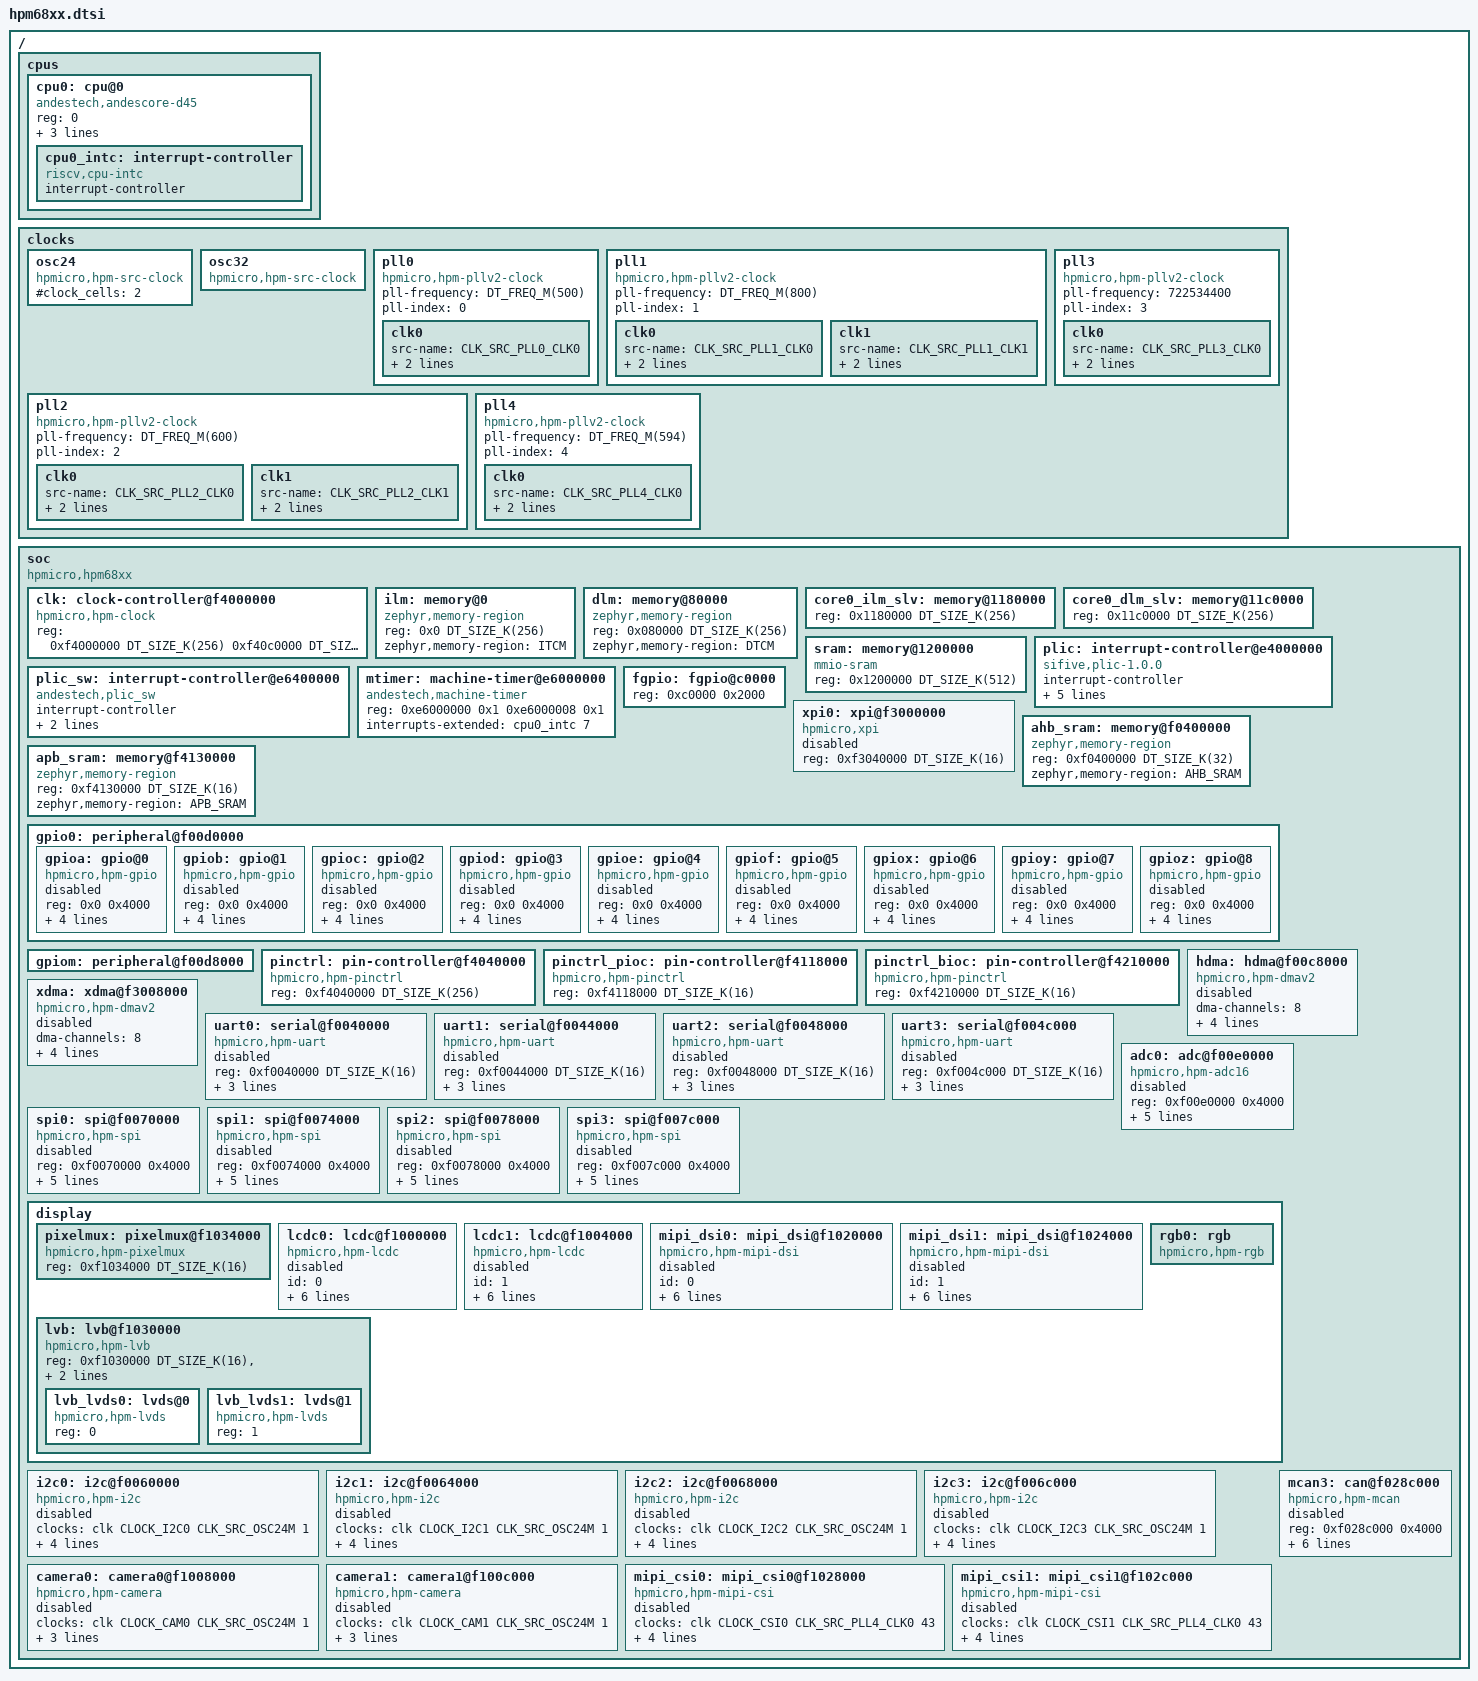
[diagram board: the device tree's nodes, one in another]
/*
 * Copyright 2024 HPMicro
 * SPDX-License-Identifier: Apache-2.0
 */

/dts-v1/;
#include <zephyr/dt-bindings/gpio/gpio.h>
#include <zephyr/dt-bindings/i2c/i2c.h>
#include <dt-bindings/clock/hpm6880-clocks.h>
#include <mem.h>
#include <freq.h>


/ {
    #address-cells = <1>;
    #size-cells = <1>;

    cpus {
        #address-cells = <1>;
        #size-cells = <0>;
        cpu0: cpu@0 {
            compatible = "andestech,andescore-d45", "riscv";
            reg = <0>;
            status = "okay";
            riscv,isa = "rv32gcp_xandes";       /* support SIMD DSP */
            i-cache-line-size = <64>;
            d-cache-line-size = <64>;

            cpu0_intc: interrupt-controller {
                compatible = "riscv,cpu-intc";
                #address-cells = <0>;
                #interrupt-cells = <1>;
                interrupt-controller;
            };
        };
    };

    clocks {
        osc24: osc24 {
            #clock_cells = <2>;
            compatible = "hpmicro,hpm-src-clock";
        };

		osc32: osc32 {
			#clock-cells = <2>;
			compatible = "hpmicro,hpm-src-clock";
		};

		pll0: pll0 {
			#clock-cells = <2>;
			compatible = "hpmicro,hpm-pllv2-clock";
			pll-frequency = <DT_FREQ_M(500)>;
			pll-index = <0>;

			clk0 {
				src-name = <CLK_SRC_PLL0_CLK0>;
				div-i = <0>;
				div-p = <0>;
			};
		};

		pll1: pll1 {
			#clock-cells = <2>;
			compatible = "hpmicro,hpm-pllv2-clock";
			pll-frequency = <DT_FREQ_M(800)>;
			pll-index = <1>;

			clk0 {
				src-name = <CLK_SRC_PLL1_CLK0>;
				div-i = <0>;
				div-p = <0>;
			};

			clk1 {
				src-name = <CLK_SRC_PLL1_CLK1>;
				div-i = <1>;
				div-p = <1>;
			};
		};

		pll2: pll2 {
			#clock-cells = <2>;
			compatible = "hpmicro,hpm-pllv2-clock";
			pll-frequency = <DT_FREQ_M(600)>;
			pll-index = <2>;

			clk0 {
				src-name = <CLK_SRC_PLL2_CLK0>;
				div-i = <0>;
				div-p = <0>;
			};

			clk1 {
				src-name = <CLK_SRC_PLL2_CLK1>;
				div-i = <1>;
				div-p = <1>;
			};
		};

		pll3: pll3 {
			#clock-cells = <2>;
			compatible = "hpmicro,hpm-pllv2-clock";
			pll-frequency = <722534400>;
			pll-index = <3>;

			clk0 {
				src-name = <CLK_SRC_PLL3_CLK0>;
				div-i = <0>;
				div-p = <2>;				
			};
		};

		pll4: pll4 {
			#clock-cells = <2>;
			compatible = "hpmicro,hpm-pllv2-clock";
			pll-frequency = <DT_FREQ_M(594)>;
			pll-index = <4>;

			clk0 {
				src-name = <CLK_SRC_PLL4_CLK0>;
				div-i = <0>;
				div-p = <0>;
			};
		};
    };

    soc {
        #address-cells = <1>;
        #size-cells = <1>;
        compatible = "hpmicro,hpm68xx";
        ranges;

        clk: clock-controller@f4000000 {
            compatible = "hpmicro,hpm-clock";
            reg = <0xf4000000 DT_SIZE_K(256)
                0xf40c0000 DT_SIZE_K(256)>;
            reg-names = "sysctl", "pll";
            #clock-cells = <3>;
            status = "okay";
        };

        ilm: memory@0 {
            compatible = "zephyr,memory-region";
            reg = <0x0 DT_SIZE_K(256)>;
            zephyr,memory-region = "ITCM";
        };

        dlm: memory@80000 {
            compatible = "zephyr,memory-region";
            reg = <0x080000 DT_SIZE_K(256)>;
            zephyr,memory-region = "DTCM";
        };

        core0_ilm_slv: memory@1180000 {
            reg = <0x1180000 DT_SIZE_K(256)>;
        };

        core0_dlm_slv: memory@11c0000 {
            reg = <0x11c0000 DT_SIZE_K(256)>;
        };

        sram: memory@1200000 {
            compatible = "mmio-sram";
            reg = <0x1200000 DT_SIZE_K(512)>;
        };

        plic: interrupt-controller@e4000000 {
            compatible = "sifive,plic-1.0.0";
            #address-cells = <1>;
            #interrupt-cells = <2>;
            interrupt-controller;
            reg = <    0xe4000000 0x00001000
                0xe4002000 0x00000800
                0xe4200000 0x00010000 >;
            reg-names = "prio", "irq_en", "reg";
            riscv,max-priority = <7>;
            riscv,ndev = <127>;
            interrupts-extended = <&cpu0_intc 11>;
        };

        plic_sw: interrupt-controller@e6400000 {
            compatible = "andestech,plic_sw";
            #address-cells = <1>;
            #interrupt-cells = <2>;
            interrupt-controller;
            reg = <0xe6400000 DT_SIZE_M(4)>;
            interrupts-extended = <&cpu0_intc 3>;
        };

        mtimer: machine-timer@e6000000 {
            compatible = "andestech,machine-timer";
            reg = <0xe6000000 0x1
            0xe6000008 0x1>;
            interrupts-extended = <&cpu0_intc 7>;
        };

        fgpio: fgpio@c0000 {
            reg = <0xc0000 0x2000>;
        };

        xpi0: xpi@f3000000 {
            compatible = "hpmicro,xpi";
            reg = <0xf3040000 DT_SIZE_K(16)>;
            #address-cells = <1>;
            #size-cells = <1>;
            status = "disabled";
        };

        ahb_sram: memory@f0400000 {
            compatible = "zephyr,memory-region";
            reg = <0xf0400000 DT_SIZE_K(32)>;
            zephyr,memory-region = "AHB_SRAM";
        };

        apb_sram: memory@f4130000 {
            compatible = "zephyr,memory-region";
            reg = <0xf4130000 DT_SIZE_K(16)>;
            zephyr,memory-region = "APB_SRAM";
        };

        gpio0: peripheral@f00d0000 {
            #address-cells = <1>;
            #size-cells = <1>;
            ranges = <0x0 0xf00d0000 DT_SIZE_K(16)>;
        };

        gpiom: peripheral@f00d8000 {
            #address-cells = <1>;
            #size-cells = <1>;
            ranges = <0x0 0xf00d8000 DT_SIZE_K(16)>;
        };

        pinctrl: pin-controller@f4040000 {
            compatible = "hpmicro,hpm-pinctrl";
            reg = <0xf4040000 DT_SIZE_K(256)>;
            status = "okay";
        };

        pinctrl_pioc: pin-controller@f4118000 {
            compatible = "hpmicro,hpm-pinctrl";
            reg = <0xf4118000 DT_SIZE_K(16)>;
            status = "okay";
        };

        pinctrl_bioc: pin-controller@f4210000 {
            compatible = "hpmicro,hpm-pinctrl";
            reg = <0xf4210000 DT_SIZE_K(16)>;
            status = "okay";
        };

        hdma: hdma@f00c8000 {
            #dma-cells = <2>;
            compatible = "hpmicro,hpm-dmav2";
            dma-channels = <8>;
            dma-requests = <116>;
            reg = <0xf00c8000 0x4000>,
                <0xf00c4000 0x4000>; /* DMAMUX base */
            interrupts = <58 1>;
            interrupt-parent = <&plic>;
            status = "disabled";
        };

        xdma: xdma@f3008000 {
            #dma-cells = <2>;
            compatible = "hpmicro,hpm-dmav2";
            dma-channels = <8>;
            dma-requests = <116>;
            reg = <0xf3048000 0x4000>,
                <0xf00c4000 0x4000>; /* DMAMUX base */
            interrupts = <99 1>;
            interrupt-parent = <&plic>;
            status = "disabled";
        };

        uart0: serial@f0040000 {
            compatible = "hpmicro,hpm-uart";
            reg = <0xf0040000 DT_SIZE_K(16)>;
            interrupts = <27 1>, <47 1>;
            interrupt-names = "uart", "idletimer";
            clocks = <&clk CLOCK_UART0 CLK_SRC_OSC24M 1>;
            interrupt-parent = <&plic>;
            status = "disabled";
        };

        uart1: serial@f0044000 {
            compatible = "hpmicro,hpm-uart";
            reg = <0xf0044000 DT_SIZE_K(16)>;
            interrupts = <28 1>, <47 1>;
            interrupt-names = "uart", "idletimer";
            clocks = <&clk CLOCK_UART1 CLK_SRC_OSC24M 1>;
            interrupt-parent = <&plic>;
            status = "disabled";
        };

        uart2: serial@f0048000 {
            compatible = "hpmicro,hpm-uart";
            reg = <0xf0048000 DT_SIZE_K(16)>;
            interrupts = <29 1>, <47 1>;
            interrupt-names = "uart", "idletimer";
            clocks = <&clk CLOCK_UART2 CLK_SRC_OSC24M 1>;
            interrupt-parent = <&plic>;
            status = "disabled";
        };

        uart3: serial@f004c000 {
            compatible = "hpmicro,hpm-uart";
            reg = <0xf004c000 DT_SIZE_K(16)>;
            interrupts = <30 1>, <47 1>;
            interrupt-names = "uart", "idletimer";
            clocks = <&clk CLOCK_UART3 CLK_SRC_OSC24M 1>;
            interrupt-parent = <&plic>;
            status = "disabled";
        };

        adc0: adc@f00e0000 {
            compatible = "hpmicro,hpm-adc16";
            reg = <0xf00e0000 0x4000>;
            interrupts = <59 1>;
            interrupt-parent = <&plic>;
            clocks = <&clk CLOCK_ADC0 CLK_ADC_SRC_ANA0 1>, <&clk CLOCK_ANA0 CLK_SRC_PLL1_CLK0 4>;
            sample-time = <20>;
            status = "disabled";
            #io-channel-cells = <1>;
        };

        spi0: spi@f0070000 {
            compatible = "hpmicro,hpm-spi";
            reg = <0xf0070000 0x4000>;
            clocks = <&clk CLOCK_SPI0 CLK_SRC_PLL1_CLK0 10>;
            interrupts = <39 1>;
            interrupt-parent = <&plic>;
            status = "disabled";
            #address-cells = <1>;
            #size-cells = <0>;
            cs-sck-delay = <3>;
            cs-minimum-high-time = <11>;
        };

        spi1: spi@f0074000 {
            compatible = "hpmicro,hpm-spi";
            reg = <0xf0074000 0x4000>;
            clocks = <&clk CLOCK_SPI1 CLK_SRC_PLL1_CLK0 10>;
            interrupts = <40 1>;
            interrupt-parent = <&plic>;
            status = "disabled";
            #address-cells = <1>;
            #size-cells = <0>;
            cs-sck-delay = <3>;
            cs-minimum-high-time = <11>;
        };

        spi2: spi@f0078000 {
            compatible = "hpmicro,hpm-spi";
            reg = <0xf0078000 0x4000>;
            clocks = <&clk CLOCK_SPI2 CLK_SRC_PLL1_CLK0 10>;
            interrupts = <41 1>;
            interrupt-parent = <&plic>;
            status = "disabled";
            #address-cells = <1>;
            #size-cells = <0>;
            cs-sck-delay = <3>;
            cs-minimum-high-time = <11>;
        };

        spi3: spi@f007c000 {
            compatible = "hpmicro,hpm-spi";
            reg = <0xf007c000 0x4000>;
            clocks = <&clk CLOCK_SPI3 CLK_SRC_PLL1_CLK0 10>;
            interrupts = <42 1>;
            interrupt-parent = <&plic>;
            status = "disabled";
            #address-cells = <1>;
            #size-cells = <0>;
            cs-sck-delay = <3>;
            cs-minimum-high-time = <11>;
        };

        display {
            #address-cells = <1>;
            #size-cells = <1>;
            pixelmux: pixelmux@f1034000 {
                compatible = "hpmicro,hpm-pixelmux";
                reg = <0xf1034000 DT_SIZE_K(16)>;
            };

            lcdc0: lcdc@f1000000 {
                compatible = "hpmicro,hpm-lcdc";
                id = <0>;
                reg = <0xf1000000 DT_SIZE_K(16)>;
                router = <&pixelmux>;
                interrupts = <73 1>;
                interrupt-parent = <&plic>;
                clocks = <&clk CLK_PLL4CLK0 CLK_SRC_OSC24M 1>, <&clk CLOCK_LCD0 CLK_SRC_PLL4_CLK0 10>;
                clock-names = "pll", "lcdc";
                status = "disabled";
            };

            lcdc1: lcdc@f1004000 {
                compatible = "hpmicro,hpm-lcdc";
                id = <1>;
                reg = <0xf1004000 DT_SIZE_K(16)>;
                router = <&pixelmux>;
                interrupts = <74 1>;
                interrupt-parent = <&plic>;
                clocks = <&clk CLK_PLL4CLK0 CLK_SRC_OSC24M 1>, <&clk CLOCK_LCD1 CLK_SRC_PLL4_CLK0 10>;
                clock-names = "pll", "lcdc";
                status = "disabled";
            };

            mipi_dsi0: mipi_dsi@f1020000 {
                compatible = "hpmicro,hpm-mipi-dsi";
                id = <0>;
                reg = <0xf1020000 DT_SIZE_K(16)>, <0xf4140000 DT_SIZE_K(16)>, <0xf1034000 DT_SIZE_K(16)>;
                reg-names = "mipi_dsi", "mipi_dsi_phy", "pixelmux";
                clocks = <&clk CLOCK_DSI0 0 0>;
                clock-names = "dsi";
                interrupts = <81 1>;
                interrupt-parent = <&plic>;
                status = "disabled";
            };

            mipi_dsi1: mipi_dsi@f1024000 {
                compatible = "hpmicro,hpm-mipi-dsi";
                id = <1>;
                reg = <0xf1024000 DT_SIZE_K(16)>, <0xf4144000 DT_SIZE_K(16)>, <0xf1034000 DT_SIZE_K(16)>;
                reg-names = "mipi_dsi", "mipi_dsi_phy", "pixelmux";
                clocks = <&clk CLOCK_DSI1 0 0>;
                clock-names = "dsi";
                interrupts = <82 1>;
                interrupt-parent = <&plic>;
                status = "disabled";
            };

            lvb: lvb@f1030000 {
                compatible = "hpmicro,hpm-lvb";
                reg = <0xf1030000 DT_SIZE_K(16)>, <0xf1034000 DT_SIZE_K(16)>;
                reg-names = "lvb", "pixelmux";
                clocks = <&clk CLOCK_LVB 0 0>;
                clock-names = "lvb";
                #address-cells = <1>;
                #size-cells = <0>;

                lvb_lvds0: lvds@0 {
                    compatible = "hpmicro,hpm-lvds";
                    reg = <0>;
                };

                lvb_lvds1: lvds@1 {
                    compatible = "hpmicro,hpm-lvds";
                    reg = <1>;
                };
            };

            rgb0: rgb {
                compatible = "hpmicro,hpm-rgb";
            };
        };

        i2c0: i2c@f0060000 {
            compatible = "hpmicro,hpm-i2c";
            #address-cells = <1>;
            #size-cells = <0>;
            clocks = <&clk CLOCK_I2C0 CLK_SRC_OSC24M 1>;
            clock-frequency = <I2C_BITRATE_STANDARD>;
            reg = <0xf0060000 0x4000>;
            interrupts = <35 1>;
            interrupt-parent = <&plic>;
            status = "disabled";
        };

        i2c1: i2c@f0064000 {
            compatible = "hpmicro,hpm-i2c";
            #address-cells = <1>;
            #size-cells = <0>;
            clocks = <&clk CLOCK_I2C1 CLK_SRC_OSC24M 1>;
            clock-frequency = <I2C_BITRATE_STANDARD>;
            reg = <0xf0064000 0x4000>;
            interrupts = <36 1>;
            interrupt-parent = <&plic>;
            status = "disabled";
        };

        i2c2: i2c@f0068000 {
            compatible = "hpmicro,hpm-i2c";
            #address-cells = <1>;
            #size-cells = <0>;
            clocks = <&clk CLOCK_I2C2 CLK_SRC_OSC24M 1>;
            clock-frequency = <I2C_BITRATE_STANDARD>;
            reg = <0xf0068000 0x4000>;
            interrupts = <37 1>;
            interrupt-parent = <&plic>;
            status = "disabled";
        };

        i2c3: i2c@f006c000 {
            compatible = "hpmicro,hpm-i2c";
            #address-cells = <1>;
            #size-cells = <0>;
            clocks = <&clk CLOCK_I2C3 CLK_SRC_OSC24M 1>;
            clock-frequency = <I2C_BITRATE_STANDARD>;
            reg = <0xf006c000 0x4000>;
            interrupts = <38 1>;
            interrupt-parent = <&plic>;
            status = "disabled";
        };

        camera0: camera0@f1008000 {
            compatible = "hpmicro,hpm-camera";
            clocks = <&clk CLOCK_CAM0 CLK_SRC_OSC24M 1>;
            reg = <0xf1008000 0x4000>;
            interrupts = <71 1>;
            interrupt-parent = <&plic>;
            status = "disabled";
        };

        camera1: camera1@f100c000 {
            compatible = "hpmicro,hpm-camera";
            clocks = <&clk CLOCK_CAM1 CLK_SRC_OSC24M 1>;
            reg = <0xf100c000 0x4000>;
            interrupts = <72 1>;
            interrupt-parent = <&plic>;
            status = "disabled";
        };

        mipi_csi0: mipi_csi0@f1028000 {
            compatible = "hpmicro,hpm-mipi-csi";
            clocks = <&clk CLOCK_CSI0 CLK_SRC_PLL4_CLK0 43>;
            reg = <0xf1028000 0x4000>;
            mipi_csi_phy_reg = <0xf4148000 0x4000>;
            interrupts = <83 1>;
            interrupt-parent = <&plic>;
            status = "disabled";
        };

        mipi_csi1: mipi_csi1@f102c000 {
            compatible = "hpmicro,hpm-mipi-csi";
            clocks = <&clk CLOCK_CSI1 CLK_SRC_PLL4_CLK0 43>;
            reg = <0xf102c000 0x4000>;
            mipi_csi_phy_reg = <0xf414c000 0x4000>;
            interrupts = <88 1>;
            interrupt-parent = <&plic>;
            status = "disabled";
        };
        mcan3: can@f028c000 {
            compatible = "hpmicro,hpm-mcan";
            reg = <0xf028c000 0x4000>;
            interrupts = <13 1>;
            interrupt-parent = <&plic>;
            clk-name = <17563648>;
            clk-source = <2>;
            clk-divider = <10>;
            bus-speed = <500000>;
            status = "disabled";
        };

    };
};

&gpio0 {
    gpioa: gpio@0 {
        compatible = "hpmicro,hpm-gpio";
        reg = <0x0 0x4000>;
        gpio-controller;
        #gpio-cells = <2>;
        hpmicro-gpio-port = <0>;
        interrupts = <1 1>;
        interrupt-parent = <&plic>;
        status = "disabled";
    };

    gpiob: gpio@1 {
        compatible = "hpmicro,hpm-gpio";
        reg = <0x0 0x4000>;
        gpio-controller;
        #gpio-cells = <2>;
        hpmicro-gpio-port = <1>;
        interrupts = <2 1>;
        interrupt-parent = <&plic>;
        status = "disabled";
    };

    gpioc: gpio@2 {
        compatible = "hpmicro,hpm-gpio";
        reg = <0x0 0x4000>;
        gpio-controller;
        #gpio-cells = <2>;
        hpmicro-gpio-port = <2>;
        interrupts = <3 1>;
        interrupt-parent = <&plic>;
        status = "disabled";
    };

    gpiod: gpio@3 {
        compatible = "hpmicro,hpm-gpio";
        reg = <0x0 0x4000>;
        gpio-controller;
        #gpio-cells = <2>;
        status = "disabled";
        hpmicro-gpio-port = <3>;
        interrupts = <4 1>;
        interrupt-parent = <&plic>;
        status = "disabled";
    };

    gpioe: gpio@4 {
        compatible = "hpmicro,hpm-gpio";
        reg = <0x0 0x4000>;
        gpio-controller;
        #gpio-cells = <2>;
        hpmicro-gpio-port = <4>;
        interrupts = <5 1>;
        interrupt-parent = <&plic>;
        status = "disabled";
    };

    gpiof: gpio@5 {
        compatible = "hpmicro,hpm-gpio";
        reg = <0x0 0x4000>;
        gpio-controller;
        #gpio-cells = <2>;
        hpmicro-gpio-port = <5>;
        interrupts = <6 1>;
        interrupt-parent = <&plic>;
        status = "disabled";
    };

    gpiox: gpio@6 {
        compatible = "hpmicro,hpm-gpio";
        reg = <0x0 0x4000>;
        gpio-controller;
        #gpio-cells = <2>;
        hpmicro-gpio-port = <13>;
        interrupt-parent = <&plic>;
        interrupts = <7 1>;
        status = "disabled";
    };

    gpioy: gpio@7 {
        compatible = "hpmicro,hpm-gpio";
        reg = <0x0 0x4000>;
        gpio-controller;
        #gpio-cells = <2>;
        hpmicro-gpio-port = <14>;
        interrupts = <8 1>;
        interrupt-parent = <&plic>;
        status = "disabled";
    };

    gpioz: gpio@8 {
        compatible = "hpmicro,hpm-gpio";
        reg = <0x0 0x4000>;
        gpio-controller;
        #gpio-cells = <2>;
        hpmicro-gpio-port = <15>;
        interrupts = <9 1>;
        interrupt-parent = <&plic>;
        status = "disabled";
    };
};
